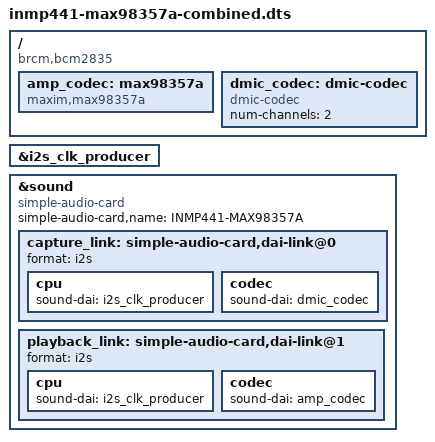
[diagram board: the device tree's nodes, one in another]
// Overlay combinado: INMP441 (captura) + MAX98357A (reproducción)
// en una sola simple-audio-card con dos enlaces DAI.
//
// Fuente: adaptado de Virgil-Zu/snd-soc-inmp441
// https://github.com/Virgil-Zu/snd-soc-inmp441/blob/main/inmp441-max98357a-overlay.dts
//
// Usa dmic-codec (snd-soc-dmic, incluido en kernel estándar) para captura
// y max98357a para reproducción, ambos en la misma tarjeta de sonido.
//
// El formato dai-link@N (simple-audio-card,dai-link@N) es necesario para
// múltiples enlaces DAI. El formato plano (simple-audio-card,cpu arrays)
// no funciona en este kernel (6.12.96).
//
// CONFIGURACIÓN:
//   dtc -@ -I dts -O dtb -o inmp441-max98357a-combined.dtbo inmp441-max98357a-combined.dts
//   sudo cp inmp441-max98357a-combined.dtbo /boot/firmware/overlays/
//   config.txt: dtoverlay=inmp441-max98357a-combined
//
// VERIFICACIÓN (tras reboot):
//   aplay -l    → card N: INMP441MAX98357 [INMP441-MAX98357A], device 0: HiFi-0 (playback)
//   arecord -l  → card N: INMP441MAX98357 [INMP441-MAX98357A], device 1: dmic-hifi-1 (capture)
/dts-v1/;
/plugin/;

/ {
    compatible = "brcm,bcm2835";

    fragment@0 {
        target = <&i2s_clk_producer>;
        __overlay__ {
            #sound-dai-cells = <0>;
            status = "okay";
        };
    };

    fragment@1 {
        target-path = "/";
        __overlay__ {
            amp_codec: max98357a {
                #sound-dai-cells = <0>;
                compatible = "maxim,max98357a";
                status = "okay";
            };

            dmic_codec: dmic-codec {
                #sound-dai-cells = <0>;
                compatible = "dmic-codec";
                num-channels = <2>;
                status = "okay";
            };
        };
    };

    fragment@2 {
        target = <&sound>;
        __overlay__ {
            compatible = "simple-audio-card";
            simple-audio-card,name = "INMP441-MAX98357A";
            status = "okay";

            capture_link: simple-audio-card,dai-link@0 {
                format = "i2s";

                cpu {
                    sound-dai = <&i2s_clk_producer>;
                };

                codec {
                    sound-dai = <&dmic_codec>;
                };
            };

            playback_link: simple-audio-card,dai-link@1 {
                format = "i2s";

                cpu {
                    sound-dai = <&i2s_clk_producer>;
                };

                codec {
                    sound-dai = <&amp_codec>;
                };
            };
        };
    };
};
